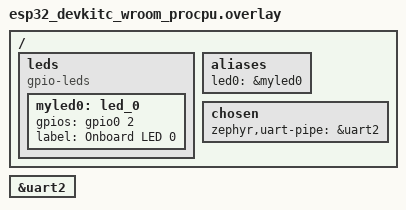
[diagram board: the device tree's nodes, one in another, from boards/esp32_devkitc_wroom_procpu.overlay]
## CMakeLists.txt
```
cmake_minimum_required(VERSION 3.13.1)
message("ZEPHYR_BASE = $ENV{ZEPHYR_BASE}")
find_package(Zephyr REQUIRED HINTS $ENV{ZEPHYR_BASE})
project(usbnet)

target_sources(app PRIVATE src/main.c)

target_compile_options(
    app
    PUBLIC
    -fmax-errors=5
    )
```

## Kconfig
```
mainmenu "serialnet demo application"

menu "App Options"
	config APP_IPV4_ADDR
	    string "IP address for the serial interface."
	    default "192.0.2.1"

	config APP_IPV4_MASK
	    string "IP netmask for the serial interface."
	    default "255.255.255.0"

	config APP_IPV4_GW
	    string "IP gateway for the serial interface."
	    default "192.0.2.2"
endmenu

source "Kconfig.zephyr"
```

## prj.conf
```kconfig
CONFIG_LOG=y
CONFIG_PRINTK=y

# Kernel options
CONFIG_MAIN_STACK_SIZE=2048
CONFIG_INIT_STACKS=y

CONFIG_SERIAL=y
CONFIG_UART_PIPE=y

# Generic networking options
CONFIG_NETWORKING=y
CONFIG_NET_ZPERF=y
CONFIG_NET_LOG=y
CONFIG_NET_UDP=y
CONFIG_NET_TCP=y
CONFIG_NET_IPV6=y
CONFIG_NET_IPV4=y
CONFIG_NET_DHCPV4=n
CONFIG_NET_STATISTICS=y
CONFIG_NET_SOCKETS=y
CONFIG_NET_SOCKETS_SERVICE_THREAD_PRIO=-1
CONFIG_NET_SOCKETS_POLL_MAX=10
CONFIG_POSIX_API=y

CONFIG_NET_BUF_DATA_SIZE=1500
CONFIG_NET_L2_ETHERNET=y
CONFIG_NET_SHELL=y

# Network application options and configuration
CONFIG_NET_CONNECTION_MANAGER=y
CONFIG_NET_CONFIG_SETTINGS=y
CONFIG_NET_CONFIG_AUTO_INIT=n
CONFIG_NET_MGMT_EVENT_QUEUE_SIZE=8
#CONFIG_NET_CONFIG_MY_IPV4_ADDR="192.0.2.1"
#CONFIG_NET_CONFIG_PEER_IPV4_ADDR="192.0.2.2"

# Custom 
CONFIG_ETH_SERIAL=y
CONFIG_ETH_SERIAL_SLIP=y

# Logging
CONFIG_NET_CONFIG_LOG_LEVEL_DBG=y
CONFIG_ETH_SERIAL_LOG_LEVEL_DBG=y
```

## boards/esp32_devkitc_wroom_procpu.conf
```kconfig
#CONFIG_WIFI_ESP32=y
#CONFIG_ESP32_WIFI_STA_AUTO_DHCPV4=y
#CONFIG_ESP32_WIFI_STA_RECONNECT=y
```

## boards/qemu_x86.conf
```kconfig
CONFIG_QEMU_ICOUNT=n
```

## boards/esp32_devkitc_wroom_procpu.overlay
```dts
/ {
	leds {
		compatible = "gpio-leds";
		myled0: led_0 {
			gpios = <&gpio0 2 GPIO_ACTIVE_HIGH>;
			label = "Onboard LED 0";
		};
	};


	aliases {
		led0 = &myled0;
	};

	chosen {
		zephyr,uart-pipe = &uart2;
	};
};

&uart2 {
	status = "okay";
};
```

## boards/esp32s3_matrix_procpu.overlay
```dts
/ {
	leds {
		compatible = "gpio-leds";
		myled0: led_0 {
			gpios = <&gpio0 2 GPIO_ACTIVE_HIGH>;
			label = "Onboard LED 0";
		};
	};

	aliases {
		led0 = &myled0;
	};
};
```

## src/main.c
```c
#include <stdbool.h>

#include <zephyr/kernel.h>
#include <zephyr/logging/log.h>
#include <zephyr/net/net_config.h>
#include <zephyr/net/net_if.h>
#include <zephyr/net/net_mgmt.h>
#include <zephyr/net/net_event.h>
#include <zephyr/net/conn_mgr_monitor.h>

/** @brief Initialize the logging module. */
LOG_MODULE_REGISTER(app, LOG_LEVEL_DBG);


#define EVENT_MASK (NET_EVENT_L4_CONNECTED | \
                    NET_EVENT_L4_DISCONNECTED)

static struct net_mgmt_event_callback mgmt_cb;
static bool connected = false;

static K_SEM_DEFINE(l4_connected, 0, 1);

static void
init_ip(void)
{
    struct net_if *iface;
    struct net_if_addr *ifaddr;
    struct in_addr my_ipv4_addr;
    struct in_addr my_ipv4_mask;
    struct in_addr my_ipv4_gw;

    iface = net_if_get_default();

    LOG_INF("Setting IP address for iface:");
    LOG_INF("  addr: %s", CONFIG_APP_IPV4_ADDR);
    LOG_INF("  mask: %s", CONFIG_APP_IPV4_MASK);
    LOG_INF("  gw  : %s", CONFIG_APP_IPV4_GW);

    net_addr_pton(AF_INET, CONFIG_APP_IPV4_ADDR, &my_ipv4_addr);
    net_addr_pton(AF_INET, CONFIG_APP_IPV4_MASK, &my_ipv4_mask);
    net_addr_pton(AF_INET, CONFIG_APP_IPV4_GW, &my_ipv4_gw);

    ifaddr = net_if_ipv4_addr_add(iface, &my_ipv4_addr, NET_ADDR_MANUAL, 0);
    if (!ifaddr)
    {
        LOG_ERR("Error setting IP address");
        return;
    }

    net_if_ipv4_set_netmask_by_addr(iface, &my_ipv4_addr, &my_ipv4_mask);
    net_if_ipv4_set_gw(iface, &my_ipv4_gw);
}

static void
l4_event_handler(
    struct net_mgmt_event_callback *cb,
    uint32_t mgmt_event,
    struct net_if *iface)
{
    ARG_UNUSED(iface);
    ARG_UNUSED(cb);

    LOG_DBG("mgmt_event = 0x%08x (EVENT_MASK = 0x%08x).",
        mgmt_event, (unsigned int)EVENT_MASK);

    switch (mgmt_event)
    {
    case NET_EVENT_L4_CONNECTED:
        LOG_DBG("NET_EVENT_L4_CONNECTED");
        connected = true;
        k_sem_give(&l4_connected);
        break;
    case NET_EVENT_L4_DISCONNECTED:
        LOG_DBG("NET_EVENT_L4_DISCONNECTED");
        if (connected)
        {
            LOG_INF("Network disconnected event");
            connected = false;
        }
        LOG_DBG("Resetting sem.");
        k_sem_reset(&l4_connected);
        break;
    case NET_EVENT_L4_IPV4_CONNECTED:
        LOG_DBG("NET_EVENT_L4_IPV4_CONNECTED");
        break;
    case NET_EVENT_L4_IPV4_DISCONNECTED:
        LOG_DBG("NET_EVENT_L4_IPV4_DISCONNECTED");
        break;
    case NET_EVENT_L4_IPV6_CONNECTED:
        LOG_DBG("NET_EVENT_L4_IPV6_CONNECTED");
        break;
    case NET_EVENT_L4_IPV6_DISCONNECTED:
        LOG_DBG("NET_EVENT_L4_IPV6_DISCONNECTED");
        break;

    default:
        break;
    }

}

static int
network_init(void)
{
    int ret;

    if (!IS_ENABLED(CONFIG_NET_CONNECTION_MANAGER))
    {
        LOG_ERR("Must set CONFIG_NET_CONNECTION_MANAGER=y in Kconfig.");
        return -1;
    }

    net_mgmt_init_event_callback(&mgmt_cb, l4_event_handler, EVENT_MASK);
    net_mgmt_add_event_callback(&mgmt_cb);
    conn_mgr_mon_resend_status();

    init_ip();

    ret = net_config_init_app(NULL, "Initializing network");
    if (ret < 0)
    {
        LOG_ERR("Failed network init (%d)", ret);
        return ret;
    }

    LOG_INF("Waiting for network connection...");

    /* Wait for the connection. */
    k_sem_take(&l4_connected, K_FOREVER);

    LOG_INF("Network connected.");

    return 0;
}

int main(void)
{
    LOG_INF("serialnet app. %u", CONFIG_NET_MGMT_EVENT_QUEUE_SIZE);
    LOG_INF("CONFIG_NET_PKT_RX_COUNT=%u", CONFIG_NET_PKT_RX_COUNT);
    LOG_INF("CONFIG_NET_BUF_RX_COUNT=%u", CONFIG_NET_BUF_RX_COUNT);
    LOG_INF("CONFIG_NET_TCP_MAX_RECV_WINDOW_SIZE=%u", CONFIG_NET_TCP_MAX_RECV_WINDOW_SIZE);

    network_init();

    while (1)
    {
        k_msleep(1000);
    }

    return 0;
}
```
